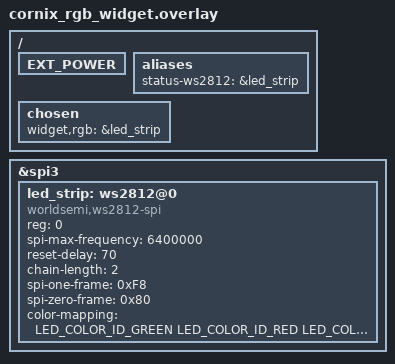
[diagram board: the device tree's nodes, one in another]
#include <zephyr/dt-bindings/led/led.h>

/ {
    EXT_POWER {
        status = "okay";
    };

    aliases {
        status-ws2812 = &led_strip;
    };

    chosen {
        widget,rgb = &led_strip;
    };
};

&spi3 {
    status = "okay";

    led_strip: ws2812@0 {
        status = "okay";
        compatible = "worldsemi,ws2812-spi";

        /* SPI */
        reg = <0>; /* ignored, but necessary for SPI bindings */
        // spi-max-frequency = <8000000>;  // 8MHz
        spi-max-frequency = <6400000>;  // 6.4 MHz (was 8 MHz)
        reset-delay = <70>;

        /* WS2812 */
        chain-length = <2>;
        // spi-one-frame = <0x78>;         // 01111000 for 1-bit (was 0x70)
        // spi-zero-frame = <0x60>;        // 01100000 for 0-bit (was 0x40)
        spi-one-frame = <0xF8>;
        spi-zero-frame = <0x80>;

        // spi-one-frame = <ONE_FRAME>;
        // spi-zero-frame = <ZERO_FRAME>;
        color-mapping = <LED_COLOR_ID_GREEN LED_COLOR_ID_RED LED_COLOR_ID_BLUE>;
    };
};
